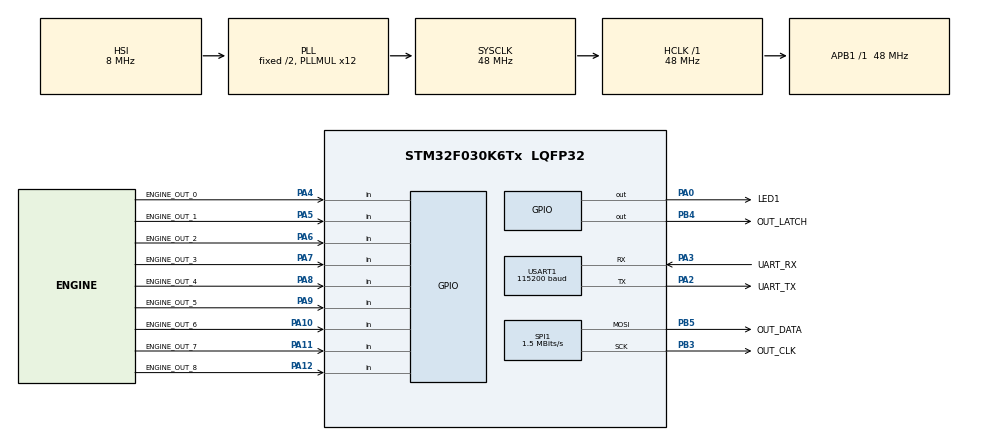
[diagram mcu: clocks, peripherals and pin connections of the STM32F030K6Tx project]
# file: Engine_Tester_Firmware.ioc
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Mcu.Family=STM32F0
SPI1.VirtualType=VM_MASTER
PA10.GPIO_PuPd=GPIO_PULLDOWN
USART1.BaudRate=115200
PA9.GPIO_Label=ENGINE_OUT_5
PA0.GPIO_Label=LED1
PA11.GPIO_Label=ENGINE_OUT_7
PA6.GPIO_Label=ENGINE_OUT_2
PA11.GPIO_PuPd=GPIO_PULLDOWN
PA9.GPIO_PuPd=GPIO_PULLDOWN
PA12.GPIO_Label=ENGINE_OUT_8
RCC.SYSCLKSource=RCC_SYSCLKSOURCE_PLLCLK
ProjectManager.StackSize=0x400
USART1.VirtualMode-Asynchronous=VM_ASYNC
PA3.Mode=Asynchronous
PA13.Signal=SYS_SWDIO
PA12.Signal=GPIO_Input
PA8.GPIO_Label=ENGINE_OUT_4
ProjectManager.TargetToolchain=STM32CubeIDE
SPI1.Direction=SPI_DIRECTION_2LINES
RCC.HCLKFreq_Value=48000000
PA9.Signal=GPIO_Input
SPI1.CalculateBaudRate=1.5 MBits/s
PA7.GPIO_PuPd=GPIO_PULLDOWN
RCC.AHBFreq_Value=48000000
PA5.Signal=GPIO_Input
PA4.GPIO_PuPd=GPIO_PULLDOWN
PB3.Mode=TX_Only_Simplex_Unidirect_Master
board=custom
RCC.PLLMUL=RCC_PLL_MUL12
PA6.GPIO_PuPd=GPIO_PULLDOWN
PB4.GPIO_Label=OUT_LATCH
SPI1.Mode=SPI_MODE_MASTER
PA14.Mode=Serial_Wire
PA5.GPIO_PuPd=GPIO_PULLDOWN
PB5.Mode=TX_Only_Simplex_Unidirect_Master
SPI1.DataSize=SPI_DATASIZE_8BIT
PA10.GPIO_Label=ENGINE_OUT_6
PA8.Signal=GPIO_Input
PA13.Mode=Serial_Wire
Mcu.Name=STM32F030K6Tx
PA2.Signal=USART1_TX
PA0.Signal=GPIO_Output
PB3.Signal=SPI1_SCK
PA4.Signal=GPIO_Input
RCC.SYSCLKFreq_VALUE=48000000
Mcu.Package=LQFP32
PB5.Signal=SPI1_MOSI
PA6.Signal=GPIO_Input
PA7.GPIO_Label=ENGINE_OUT_3
PA5.GPIO_Label=ENGINE_OUT_1
PA2.GPIO_Label=UART_TX
PA11.Signal=GPIO_Input
PA10.Signal=GPIO_Input
PA14.Signal=SYS_SWCLK
ProjectManager.HeapSize=0x200
PA8.GPIO_PuPd=GPIO_PULLDOWN
PB5.GPIO_Label=OUT_DATA
RCC.APB1TimFreq_Value=48000000
PA2.Mode=Asynchronous
PA12.GPIO_PuPd=GPIO_PULLDOWN
RCC.APB1Freq_Value=48000000
SPI1.BaudRatePrescaler=SPI_BAUDRATEPRESCALER_32
PA4.GPIO_Label=ENGINE_OUT_0
PB4.Signal=GPIO_Output
PA3.GPIO_Label=UART_RX
PA3.Signal=USART1_RX
PA7.Signal=GPIO_Input
PB3.GPIO_Label=OUT_CLK

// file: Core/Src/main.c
/* USER CODE BEGIN Header */
/**
  ******************************************************************************
  * @file           : main.c
  * @brief          : Main program body
  ******************************************************************************
  * @attention
  *
  * <h2><center>&copy; Copyright (c) 2021 STMicroelectronics.
  * All rights reserved.</center></h2>
  *
  * This software component is licensed by ST under BSD 3-Clause license,
  * the "License"; You may not use this file except in compliance with the
  * License. You may obtain a copy of the License at:
  *                        opensource.org/licenses/BSD-3-Clause
  *
  ******************************************************************************
  */
/* USER CODE END Header */
#include "main.h"

/* USER CODE BEGIN Includes */
#include "EngineTester.h"

/* USER CODE END Includes */

SPI_HandleTypeDef hspi1;

UART_HandleTypeDef huart1;

void SystemClock_Config(void);
static void MX_GPIO_Init(void);
static void MX_SPI1_Init(void);
static void MX_USART1_UART_Init(void);

int main(void)
{

  /* MCU Configuration--------------------------------------------------------*/

  /* Reset of all peripherals, Initializes the Flash interface and the Systick. */
  HAL_Init();

  /* Configure the system clock */
  SystemClock_Config();

  /* Initialize all configured peripherals */
  MX_GPIO_Init();
  MX_SPI1_Init();
  MX_USART1_UART_Init();
  /* USER CODE BEGIN 2 */

  EngineTester(); // Never returns.

  /* USER CODE END 2 */

  /* Infinite loop */
  while (1)
  {

  }
}

void SystemClock_Config(void)
{
  RCC_OscInitTypeDef RCC_OscInitStruct = {0};
  RCC_ClkInitTypeDef RCC_ClkInitStruct = {0};
  RCC_PeriphCLKInitTypeDef PeriphClkInit = {0};

  /** Initializes the RCC Oscillators according to the specified parameters
  * in the RCC_OscInitTypeDef structure.
  */
  RCC_OscInitStruct.OscillatorType = RCC_OSCILLATORTYPE_HSI;
  RCC_OscInitStruct.HSIState = RCC_HSI_ON;
  RCC_OscInitStruct.HSICalibrationValue = RCC_HSICALIBRATION_DEFAULT;
  RCC_OscInitStruct.PLL.PLLState = RCC_PLL_ON;
  RCC_OscInitStruct.PLL.PLLSource = RCC_PLLSOURCE_HSI;
  RCC_OscInitStruct.PLL.PLLMUL = RCC_PLL_MUL12;
  RCC_OscInitStruct.PLL.PREDIV = RCC_PREDIV_DIV1;
  if (HAL_RCC_OscConfig(&RCC_OscInitStruct) != HAL_OK)
  {
    Error_Handler();
  }
  /** Initializes the CPU, AHB and APB buses clocks
  */
  RCC_ClkInitStruct.ClockType = RCC_CLOCKTYPE_HCLK|RCC_CLOCKTYPE_SYSCLK
                              |RCC_CLOCKTYPE_PCLK1;
  RCC_ClkInitStruct.SYSCLKSource = RCC_SYSCLKSOURCE_PLLCLK;
  RCC_ClkInitStruct.AHBCLKDivider = RCC_SYSCLK_DIV1;
  RCC_ClkInitStruct.APB1CLKDivider = RCC_HCLK_DIV1;

  if (HAL_RCC_ClockConfig(&RCC_ClkInitStruct, FLASH_LATENCY_1) != HAL_OK)
  {
    Error_Handler();
  }
  PeriphClkInit.PeriphClockSelection = RCC_PERIPHCLK_USART1;
  PeriphClkInit.Usart1ClockSelection = RCC_USART1CLKSOURCE_PCLK1;
  if (HAL_RCCEx_PeriphCLKConfig(&PeriphClkInit) != HAL_OK)
  {
    Error_Handler();
  }
}

static void MX_SPI1_Init(void)
{

  /* SPI1 parameter configuration*/
  hspi1.Instance = SPI1;
  hspi1.Init.Mode = SPI_MODE_MASTER;
  hspi1.Init.Direction = SPI_DIRECTION_2LINES;
  hspi1.Init.DataSize = SPI_DATASIZE_8BIT;
  hspi1.Init.CLKPolarity = SPI_POLARITY_LOW;
  hspi1.Init.CLKPhase = SPI_PHASE_1EDGE;
  hspi1.Init.NSS = SPI_NSS_SOFT;
  hspi1.Init.BaudRatePrescaler = SPI_BAUDRATEPRESCALER_32;
  hspi1.Init.FirstBit = SPI_FIRSTBIT_MSB;
  hspi1.Init.TIMode = SPI_TIMODE_DISABLE;
  hspi1.Init.CRCCalculation = SPI_CRCCALCULATION_DISABLE;
  hspi1.Init.CRCPolynomial = 7;
  hspi1.Init.CRCLength = SPI_CRC_LENGTH_DATASIZE;
  hspi1.Init.NSSPMode = SPI_NSS_PULSE_ENABLE;
  if (HAL_SPI_Init(&hspi1) != HAL_OK)
  {
    Error_Handler();
  }

}

static void MX_USART1_UART_Init(void)
{

  huart1.Instance = USART1;
  huart1.Init.BaudRate = 115200;
  huart1.Init.WordLength = UART_WORDLENGTH_8B;
  huart1.Init.StopBits = UART_STOPBITS_1;
  huart1.Init.Parity = UART_PARITY_NONE;
  huart1.Init.Mode = UART_MODE_TX_RX;
  huart1.Init.HwFlowCtl = UART_HWCONTROL_NONE;
  huart1.Init.OverSampling = UART_OVERSAMPLING_16;
  huart1.Init.OneBitSampling = UART_ONE_BIT_SAMPLE_DISABLE;
  huart1.AdvancedInit.AdvFeatureInit = UART_ADVFEATURE_NO_INIT;
  if (HAL_UART_Init(&huart1) != HAL_OK)
  {
    Error_Handler();
  }

}

static void MX_GPIO_Init(void)
{
  GPIO_InitTypeDef GPIO_InitStruct = {0};

  /* GPIO Ports Clock Enable */
  __HAL_RCC_GPIOA_CLK_ENABLE();
  __HAL_RCC_GPIOB_CLK_ENABLE();

  /*Configure GPIO pin Output Level */
  HAL_GPIO_WritePin(LED1_GPIO_Port, LED1_Pin, GPIO_PIN_RESET);

  /*Configure GPIO pin Output Level */
  HAL_GPIO_WritePin(OUT_LATCH_GPIO_Port, OUT_LATCH_Pin, GPIO_PIN_RESET);

  /*Configure GPIO pin : LED1_Pin */
  GPIO_InitStruct.Pin = LED1_Pin;
  GPIO_InitStruct.Mode = GPIO_MODE_OUTPUT_PP;
  GPIO_InitStruct.Pull = GPIO_NOPULL;
  GPIO_InitStruct.Speed = GPIO_SPEED_FREQ_LOW;
  HAL_GPIO_Init(LED1_GPIO_Port, &GPIO_InitStruct);

  /*Configure GPIO pins : ENGINE_OUT_0_Pin ENGINE_OUT_1_Pin ENGINE_OUT_2_Pin ENGINE_OUT_3_Pin
                           ENGINE_OUT_4_Pin ENGINE_OUT_5_Pin ENGINE_OUT_6_Pin ENGINE_OUT_7_Pin
                           ENGINE_OUT_8_Pin */
  GPIO_InitStruct.Pin = ENGINE_OUT_0_Pin|ENGINE_OUT_1_Pin|ENGINE_OUT_2_Pin|ENGINE_OUT_3_Pin
                          |ENGINE_OUT_4_Pin|ENGINE_OUT_5_Pin|ENGINE_OUT_6_Pin|ENGINE_OUT_7_Pin
                          |ENGINE_OUT_8_Pin;
  GPIO_InitStruct.Mode = GPIO_MODE_INPUT;
  GPIO_InitStruct.Pull = GPIO_PULLDOWN;
  HAL_GPIO_Init(GPIOA, &GPIO_InitStruct);

  /*Configure GPIO pin : OUT_LATCH_Pin */
  GPIO_InitStruct.Pin = OUT_LATCH_Pin;
  GPIO_InitStruct.Mode = GPIO_MODE_OUTPUT_PP;
  GPIO_InitStruct.Pull = GPIO_NOPULL;
  GPIO_InitStruct.Speed = GPIO_SPEED_FREQ_LOW;
  HAL_GPIO_Init(OUT_LATCH_GPIO_Port, &GPIO_InitStruct);

}

void Error_Handler(void)
{
  __disable_irq();
  while (1)
  {
  }
}

/************************ (C) COPYRIGHT STMicroelectronics *****END OF FILE****/
